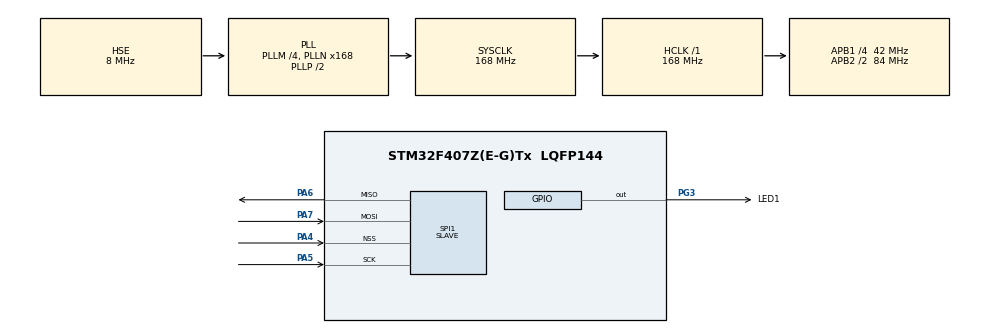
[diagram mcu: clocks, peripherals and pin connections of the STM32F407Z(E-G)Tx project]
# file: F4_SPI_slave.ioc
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Mcu.Family=STM32F4
Mcu.Name=STM32F407Z(E-G)Tx
Mcu.Package=LQFP144
NVIC.PriorityGroup=NVIC_PRIORITYGROUP_4
NVIC.SPI1_IRQn=true\:0\:0\:false\:false\:true\:true\:true
PA13.Mode=Serial_Wire
PA13.Signal=SYS_JTMS-SWDIO
PA14.Mode=Serial_Wire
PA14.Signal=SYS_JTCK-SWCLK
PA4.Mode=NSS_Signal_Hard_Input
PA4.Signal=SPI1_NSS
PA5.Mode=Full_Duplex_Slave
PA5.Signal=SPI1_SCK
PA6.Mode=Full_Duplex_Slave
PA6.Signal=SPI1_MISO
PA7.Mode=Full_Duplex_Slave
PA7.Signal=SPI1_MOSI
PC14-OSC32_IN.Mode=LSE-External-Oscillator
PC14-OSC32_IN.Signal=RCC_OSC32_IN
PC15-OSC32_OUT.Mode=LSE-External-Oscillator
PC15-OSC32_OUT.Signal=RCC_OSC32_OUT
PG3.GPIO_Label=LED1
PG3.GPIO_ModeDefaultOutputPP=GPIO_MODE_OUTPUT_OD
PG3.Signal=GPIO_Output
PH0-OSC_IN.Mode=HSE-External-Oscillator
PH0-OSC_IN.Signal=RCC_OSC_IN
PH1-OSC_OUT.Mode=HSE-External-Oscillator
PH1-OSC_OUT.Signal=RCC_OSC_OUT
ProjectManager.HeapSize=0x200
ProjectManager.StackSize=0x400
ProjectManager.TargetToolchain=STM32CubeIDE
RCC.48MHZClocksFreq_Value=84000000
RCC.AHBFreq_Value=168000000
RCC.APB1CLKDivider=RCC_HCLK_DIV4
RCC.APB1Freq_Value=42000000
RCC.APB1TimFreq_Value=84000000
RCC.APB2CLKDivider=RCC_HCLK_DIV2
RCC.APB2Freq_Value=84000000
RCC.APB2TimFreq_Value=168000000
RCC.CortexFreq_Value=168000000
RCC.HCLKFreq_Value=168000000
RCC.HSE_VALUE=8000000
RCC.HSI_VALUE=16000000
RCC.PLLM=4
RCC.PLLN=168
RCC.PLLSourceVirtual=RCC_PLLSOURCE_HSE
RCC.SYSCLKFreq_VALUE=168000000
RCC.SYSCLKSource=RCC_SYSCLKSOURCE_PLLCLK
RCC.VCOOutputFreq_Value=336000000
SPI1.Direction=SPI_DIRECTION_2LINES
SPI1.Mode=SPI_MODE_SLAVE
SPI1.VirtualNSS=VM_NSSHARD
SPI1.VirtualType=VM_SLAVE
board=custom

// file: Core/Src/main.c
/* USER CODE BEGIN Header */
/**
  ******************************************************************************
  * @file           : main.c
  * @brief          : Main program body
  ******************************************************************************
  * @attention
  *
  * <h2><center>&copy; Copyright (c) 2020 STMicroelectronics.
  * All rights reserved.</center></h2>
  *
  * This software component is licensed by ST under BSD 3-Clause license,
  * the "License"; You may not use this file except in compliance with the
  * License. You may obtain a copy of the License at:
  *                        opensource.org/licenses/BSD-3-Clause
  *
  ******************************************************************************
  */
/* USER CODE END Header */

#include "main.h"
#include "spi.h"
#include "gpio.h"

/* USER CODE BEGIN PV */
uint8_t Tx_Buffer[20] = {0};
uint8_t Rx_Buffer[20] = {0};
/* USER CODE END PV */

void SystemClock_Config(void);

int main(void)
{

  /* MCU Configuration--------------------------------------------------------*/

  /* Reset of all peripherals, Initializes the Flash interface and the Systick. */
  HAL_Init();

  /* Configure the system clock */
  SystemClock_Config();

  /* Initialize all configured peripherals */
  MX_GPIO_Init();
  MX_SPI1_Init();
  /* USER CODE BEGIN 2 */
  HAL_SPI_TransmitReceive_IT(&hspi1, Tx_Buffer, Rx_Buffer, 11);
  /* USER CODE END 2 */

  /* Infinite loop */
  /* USER CODE BEGIN WHILE */
  while (1)
  {
	HAL_GPIO_WritePin(LED1_GPIO_Port, LED1_Pin, SET);
	 HAL_Delay(50);
	 HAL_GPIO_WritePin(LED1_GPIO_Port, LED1_Pin, RESET);
	 // HAL_GPIO_TogglePin(LED1_GPIO_Port, LED1_Pin);
	  HAL_Delay(10);
    /* USER CODE END WHILE */

  }
}

void SystemClock_Config(void)
{
  RCC_OscInitTypeDef RCC_OscInitStruct = {0};
  RCC_ClkInitTypeDef RCC_ClkInitStruct = {0};

  /** Configure the main internal regulator output voltage
  */
  __HAL_RCC_PWR_CLK_ENABLE();
  __HAL_PWR_VOLTAGESCALING_CONFIG(PWR_REGULATOR_VOLTAGE_SCALE1);
  /** Initializes the CPU, AHB and APB busses clocks
  */
  RCC_OscInitStruct.OscillatorType = RCC_OSCILLATORTYPE_HSE;
  RCC_OscInitStruct.HSEState = RCC_HSE_ON;
  RCC_OscInitStruct.PLL.PLLState = RCC_PLL_ON;
  RCC_OscInitStruct.PLL.PLLSource = RCC_PLLSOURCE_HSE;
  RCC_OscInitStruct.PLL.PLLM = 4;
  RCC_OscInitStruct.PLL.PLLN = 168;
  RCC_OscInitStruct.PLL.PLLP = RCC_PLLP_DIV2;
  RCC_OscInitStruct.PLL.PLLQ = 4;
  if (HAL_RCC_OscConfig(&RCC_OscInitStruct) != HAL_OK)
  {
    Error_Handler();
  }
  /** Initializes the CPU, AHB and APB busses clocks
  */
  RCC_ClkInitStruct.ClockType = RCC_CLOCKTYPE_HCLK|RCC_CLOCKTYPE_SYSCLK
                              |RCC_CLOCKTYPE_PCLK1|RCC_CLOCKTYPE_PCLK2;
  RCC_ClkInitStruct.SYSCLKSource = RCC_SYSCLKSOURCE_PLLCLK;
  RCC_ClkInitStruct.AHBCLKDivider = RCC_SYSCLK_DIV1;
  RCC_ClkInitStruct.APB1CLKDivider = RCC_HCLK_DIV4;
  RCC_ClkInitStruct.APB2CLKDivider = RCC_HCLK_DIV2;

  if (HAL_RCC_ClockConfig(&RCC_ClkInitStruct, FLASH_LATENCY_5) != HAL_OK)
  {
    Error_Handler();
  }
}

/* USER CODE BEGIN 4 */
uint8_t temp = 0;
void HAL_SPI_TxRxCpltCallback(SPI_HandleTypeDef *hspi) {
	if(hspi->Instance == hspi1.Instance) {
		temp++;
		if(temp == 2) {
			HAL_GPIO_TogglePin(LED1_GPIO_Port, LED1_Pin);
		}

		HAL_SPI_TransmitReceive_IT(&hspi1, Tx_Buffer, Rx_Buffer, 4);
	}

}
/* USER CODE END 4 */

void Error_Handler(void)
{
}

/************************ (C) COPYRIGHT STMicroelectronics *****END OF FILE****/
